# ATSAML11E16A device description
Architecture: CORTEX-M23; Family: SAML; Series: SAML11
Registers are 32-bit, read-write, reset 0x0 unless marked. A register's access mark holds for its fields unless they carry their own. Offsets are from the block's base; [hi:lo] are bit positions; {n}, {i} and the like mark numbered series; <NAME> marks a mode.

## FPB — Flash Patch and Breakpoint
Instances: FPB 0xE0002000
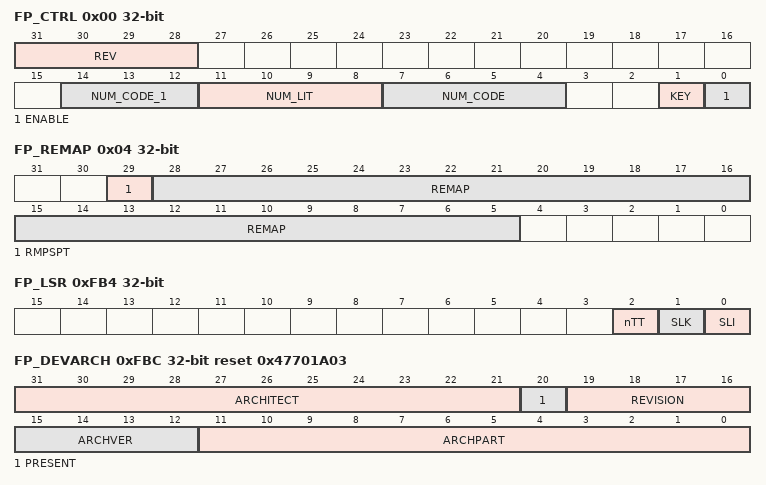
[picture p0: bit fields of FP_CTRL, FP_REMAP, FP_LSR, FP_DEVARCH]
0x00 FP_CTRL reset not defined — Flash Patch Control Register
  [31:28] REV — Revision
  [14:12] NUM_CODE_1 — Number of implemented code comparators bits [6:4]
  [11:8] NUM_LIT — Number of literal comparators
  [7:4] NUM_CODE — Number of implemented code comparators bits [3:0]
  [1] KEY — FP_CTRL write-enable key
  [0] ENABLE — Flash Patch global enable
0x04 FP_REMAP ro reset not defined — Flash Patch Remap Register
  [29] RMPSPT — Remap supported
  [28:5] REMAP — Remap address
{0x8+4i} FP_COMP[{i}] (i=0..3) reset not defined — Flash Patch Comparator Register n
  [0] BE — Breakpoint enable
  [31:1] BPADDR <BREAKPOINT> — Breakpoint address
  [31] FE <DEFAULT> — Flash Patch enable
  [28:2] FPADDR <DEFAULT> — Flash Patch address
0xFB0 FP_LAR wo reset not defined — FPB Software Lock Access Register
  [31:0] KEY — Lock access control
    0xC5ACCE55=UNLOCK (Unlock key value)
0xFB4 FP_LSR ro reset not defined — FPB Software Lock Status Register
  [2] nTT — Not thirty-two bit
  [1] SLK — Software Lock status
  [0] SLI — Software Lock implemented
0xFBC FP_DEVARCH ro reset 0x47701A03 — FPB Device Architecture Register
  [31:21] ARCHITECT
  [20] PRESENT — DEVARCH Present
  [19:16] REVISION
  [15:12] ARCHVER — Architecture Version
  [11:0] ARCHPART — Architecture Part
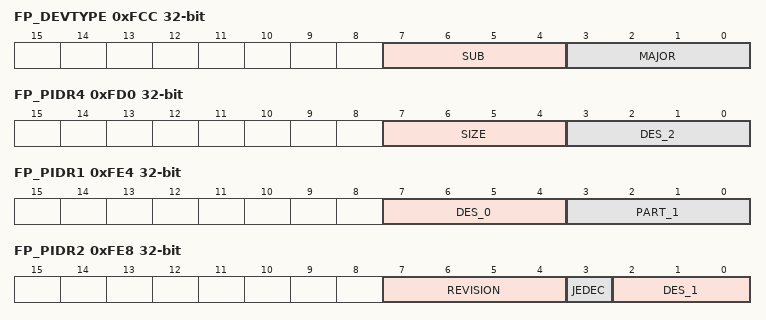
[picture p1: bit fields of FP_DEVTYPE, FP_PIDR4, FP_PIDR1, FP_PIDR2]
0xFCC FP_DEVTYPE ro — FPB Device Type Register
  [7:4] SUB — Sub-type
  [3:0] MAJOR — Major type
0xFD0 FP_PIDR4 ro reset not defined — FP Peripheral Identification Register 4
  [7:4] SIZE — 4KB count
  [3:0] DES_2 — JEP106 continuation code
{0xFC0+4i} FP_PIDR{i} ro (i=5..7) — FP Peripheral Identification Register {i}
0xFE0 FP_PIDR0 ro reset not defined — FP Peripheral Identification Register 0
  [7:0] PART_0 — Part number bits[7:0]
0xFE4 FP_PIDR1 ro reset not defined — FP Peripheral Identification Register 1
  [7:4] DES_0 — JEP106 identification code bits [3:0]
  [3:0] PART_1 — Part number bits[11:8]
0xFE8 FP_PIDR2 ro reset not defined — FP Peripheral Identification Register 2
  [7:4] REVISION — Component revision
  [3] JEDEC — JEDEC assignee value is used
  [2:0] DES_1 — JEP106 identification code bits[6:4]
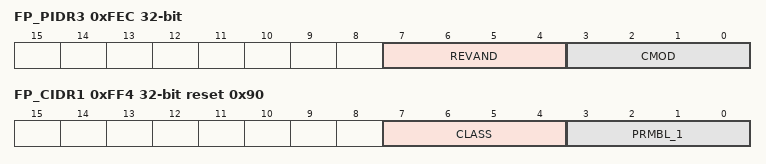
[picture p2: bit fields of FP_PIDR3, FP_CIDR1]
0xFEC FP_PIDR3 ro reset not defined — FP Peripheral Identification Register 3
  [7:4] REVAND
  [3:0] CMOD — Customer Modified
0xFF0 FP_CIDR0 ro reset 0xD — FP Component Identification Register 0
  [7:0] PRMBL_0 — CoreSight component identification preamble
0xFF4 FP_CIDR1 ro reset 0x90 — FP Component Identification Register 1
  [7:4] CLASS — CoreSight component class
  [3:0] PRMBL_1 — CoreSight component identification preamble
0xFF8 FP_CIDR2 ro reset 0x5 — FP Component Identification Register 2
  [7:0] PRMBL_2 — CoreSight component identification preamble
0xFFC FP_CIDR3 ro reset 0xB1 — FP Component Identification Register 3
  [7:0] PRMBL_3 — CoreSight component identification preamble

## ICB — Implementation Control Block
Instances: ICB 0xE000E000, ICB_NS 0xE002E000
0x04 ICTR ro reset not defined — Interrupt Controller Type Register
  [3:0] INTLINESNUM — Interrupt line set number
0x08 ACTLR reset not defined — Auxiliary Control Register

## MPU — Memory Protection Unit
Instances: MPU 0xE000ED90, MPU_NS 0xE002ED90
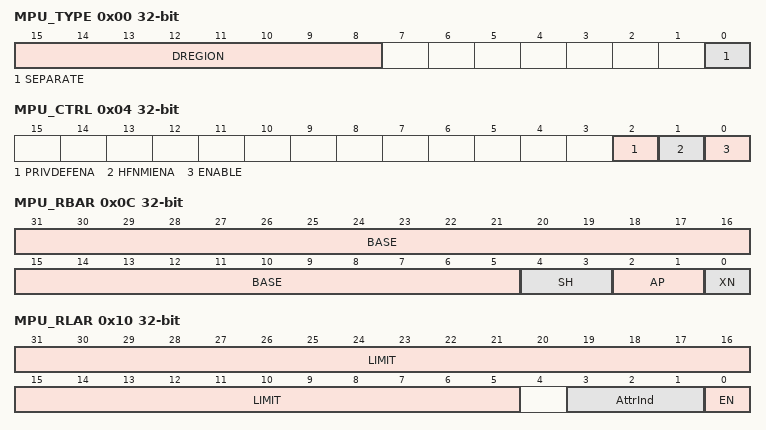
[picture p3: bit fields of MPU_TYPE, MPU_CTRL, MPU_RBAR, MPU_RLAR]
0x00 MPU_TYPE ro reset not defined
  [15:8] DREGION — Number of MPU data regions
  [0] SEPARATE — Separate instructions and data address regions
0x04 MPU_CTRL reset not defined — MPU Control Register
  [2] PRIVDEFENA — Privileged default enable
  [1] HFNMIENA — HardFault, NMI enable
  [0] ENABLE — MPU enable
0x08 MPU_RNR reset not defined — MPU Region Number Register
  [7:0] REGION — Selected region number
0x0C MPU_RBAR reset not defined — MPU Region Base Address Register
  [31:5] BASE — Base address
  [4:3] SH — Shareability
    0=NO (Non-shareable); 2=OUTER (Outer shareable); 3=INNER (Inner shareable)
  [2:1] AP — Access permissions
    0=RWPRIV (Read/write by privileged code only); 1=RWANY (Read/write by any privilege level); 2=RPRIV (Read-only by privileged code only); 3=RANY (Read-only by any privilege level)
  [0] XN — Execute Never
0x10 MPU_RLAR reset not defined — MPU Region Limit Address Register
  [31:5] LIMIT — Limit address
  [3:1] AttrInd — Attribute Index
  [0] EN — Region enable
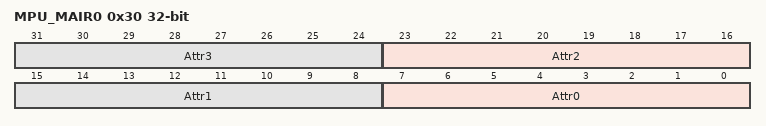
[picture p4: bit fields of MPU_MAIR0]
0x30 MPU_MAIR0 reset not defined — MPU Memory Attribute Indirection Register 0
  [8n+7:8n] Attr{n} (n=0..3) — Attribute of MPU region {n}
0x34 MPU_MAIR1 reset not defined — MPU Memory Attribute Indirection Register 1

## NVIC — Nested Vectored Interrupt Controller
Instances: NVIC 0xE000E100, NVIC_NS 0xE002E100
{0x0+4i} NVIC_ISER[{i}] (i=0..1) reset not defined — Interrupt Set Enable Register n
  [31:0] SETENA — Set enable
{0x80+4i} NVIC_ICER[{i}] (i=0..1) reset not defined — Interrupt Clear Enable Register n
  [31:0] CLRENA — Clear enable
{0x100+4i} NVIC_ISPR[{i}] (i=0..1) reset not defined — Interrupt Set Pending Register n
  [31:0] SETPEND — Set pending
{0x180+4i} NVIC_ICPR[{i}] (i=0..1) reset not defined — Interrupt Clear Pending Register n
  [31:0] CLRPEND — Clear pending
{0x200+4i} NVIC_IABR[{i}] (i=0..1) ro reset not defined — Interrupt Active Bit Register n
  [31:0] ACTIVE — Active state
{0x280+4i} NVIC_ITNS[{i}] (i=0..1) reset not defined — Interrupt Target Non-secure Register n
  [31:0] ITNS — Interrupt Targets Non-secure
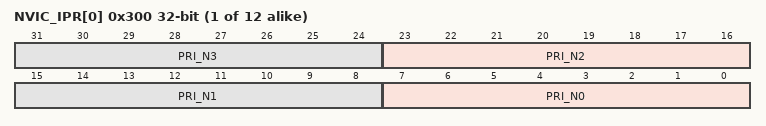
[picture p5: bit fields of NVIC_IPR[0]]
{0x300+4i} NVIC_IPR[{i}] (i=0..11) reset not defined — Interrupt Priority Register n
  [8n+7:8n] PRI_N{n} (n=0..3) — Priority of interrupt number 4n+{n}

## SysTick — SysTick Timer
Instances: SysTick 0xE000E010, SysTick_NS 0xE002E010
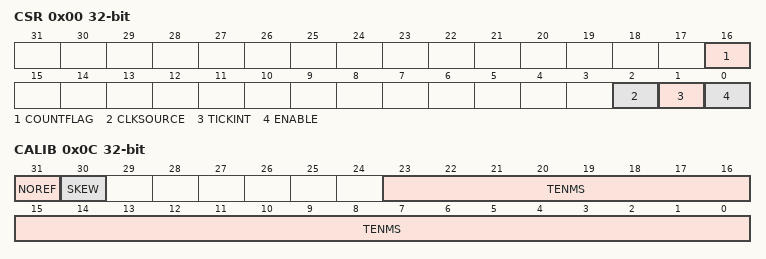
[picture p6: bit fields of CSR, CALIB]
0x00 CSR reset not defined — SysTick Control and Status Register
  [16] COUNTFLAG
  [2] CLKSOURCE — Clock source
  [1] TICKINT — Tick interrupt
  [0] ENABLE — SysTick enable
0x04 RVR reset not defined — SysTick Reload Value Register
  [24] RELOAD — Counter reload value
0x08 CVR reset not defined — SysTick Current Value Register
  [24] CURRENT — Current counter value
0x0C CALIB ro reset not defined — SysTick Calibration Value Register
  [31] NOREF — No reference
  [30] SKEW
  [23:0] TENMS — Ten milliseconds

## Notices in the file
Copyright (c) 2019 Microchip Technology Inc.
SPDX-License-Identifier: Apache-2.0
Licensed under the Apache License, Version 2.0 (the "License");
you may not use this file except in compliance with the License.
You may obtain a copy of the License at
http://www.apache.org/licenses/LICENSE-2.0
Unless required by applicable law or agreed to in writing, software
distributed under the License is distributed on an "AS IS" BASIS,
WITHOUT WARRANTIES OR CONDITIONS OF ANY KIND, either express or implied.
See the License for the specific language governing permissions and
limitations under the License.
